# LPC55S66_cm33_core1 register map
Vendor: nxp.com; File version: 1.0
CPU: CM33 r2p0, little endian, no MPU, no FPU, VTOR, 3 interrupt priority bits
Registers are 32-bit, read-write, reset 0x0 unless marked. A register's access mark holds for its fields unless they carry their own. Offsets are from the block's base; [hi:lo] are bit positions; {n}, {i} and the like mark numbered series.

## RTC — Real-Time Clock (RTC)
Base 0x4002C000
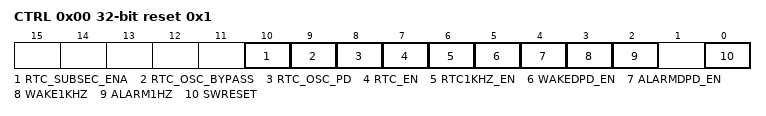
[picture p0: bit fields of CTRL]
0x00 CTRL reset 0x1 — RTC control register
  [10] RTC_SUBSEC_ENA — RTC Sub-second counter control.
    0=POWER_UP (The sub-second counter (if implemented) is disabled. This bit is cleared by a system-level POR or BOD reset as well as a by the RTC_ENA bit (bit 7 in this register). On modules not equipped with a sub-second counter, this bit will always read-back as a '0'.); 1=POWERED_DOWN (The 32 KHz sub-second counter is enabled (if implemented). Counting commences on the start of the first one-second interval after this bit is set. Note: This bit can only be set after the RTC_ENA bit (bit 7) is set by a previous write operation. Note: The RTC sub-second counter must be re-enabled whenever the chip exits deep power-down mode.)
  [9] RTC_OSC_BYPASS — RTC oscillator bypass control.
    0=USED (The RTC Oscillator operates normally as a crystal oscillator with the crystal connected between the RTC_XTALIN and RTC_XTALOUT pins.); 1=BYPASS (The RTC Oscillator is in bypass mode. In this mode a clock can be directly input into the RTC_XTALIN pin.)
  [8] RTC_OSC_PD — RTC oscillator power-down control.
    0=POWER_UP (See RTC_OSC_BYPASS); 1=POWERED_DOWN (RTC oscillator is powered-down.)
  [7] RTC_EN — RTC enable.
    0=DISABLE (Disable. The RTC 1 Hz and 1 kHz clocks are shut down and the RTC operation is disabled. This bit should be 0 when writing to load a value in the RTC counter register.); 1=ENABLE (Enable. The 1 Hz RTC clock is running and RTC operation is enabled. This bit must be set to initiate operation of the RTC. The first clock to the RTC counter occurs 1 s after this bit is set. To also enable the high-resolution, 1 kHz clock, set bit 6 in this register.)
  [6] RTC1KHZ_EN — RTC 1 kHz clock enable. This bit can be set to 0 to conserve power if the 1 kHz timer is not used. This bit has no effect when the RTC is disabled (bit 7 of this register is 0).
    0=DISABLE (Disable. A match on the 1 kHz RTC timer will not bring the part out of Deep power-down mode.); 1=ENABLE (Enable. The 1 kHz RTC timer is enabled.)
  [5] WAKEDPD_EN — RTC 1 kHz timer wake-up enable for Deep power-down.
    0=DISABLE (Disable. A match on the 1 kHz RTC timer will not bring the part out of Deep power-down mode.); 1=ENABLE (Enable. A match on the 1 kHz RTC timer bring the part out of Deep power-down mode.)
  [4] ALARMDPD_EN — RTC 1 Hz timer alarm enable for Deep power-down.
    0=DISABLE (Disable. A match on the 1 Hz RTC timer will not bring the part out of Deep power-down mode.); 1=ENABLE (Enable. A match on the 1 Hz RTC timer bring the part out of Deep power-down mode.)
  [3] WAKE1KHZ — RTC 1 kHz timer wake-up flag status.
    0=RUN (Run. The RTC 1 kHz timer is running. Writing a 0 has no effect.); 1=TIMEOUT (Time-out. The 1 kHz high-resolution/wake-up timer has timed out. This flag generates an RTC wake-up interrupt request RTC-WAKE which can also wake up the part from any low power mode. Writing a 1 clears this bit.)
  [2] ALARM1HZ — RTC 1 Hz timer alarm flag status.
    0=NO_MATCH (No match. No match has occurred on the 1 Hz RTC timer. Writing a 0 has no effect.); 1=MATCH (Match. A match condition has occurred on the 1 Hz RTC timer. This flag generates an RTC alarm interrupt request RTC_ALARM which can also wake up the part from any low power mode. Writing a 1 clears this bit.)
  [0] SWRESET — Software reset control
    0=NOT_IN_RESET (Not in reset. The RTC is not held in reset. This bit must be cleared prior to configuring or initiating any operation of the RTC.); 1=IN_RESET (In reset. The RTC is held in reset. All register bits within the RTC will be forced to their reset value except the OFD bit. This bit must be cleared before writing to any register in the RTC - including writes to set any of the other bits within this register. Do not attempt to write to any bits of this register at the same time that the reset bit is being cleared.)
0x04 MATCH reset 0xFFFFFFFF — RTC match register
  [31:0] MATVAL — Contains the match value against which the 1 Hz RTC timer will be compared to set the alarm flag RTC_ALARM and generate an alarm interrupt/wake-up if enabled.
0x08 COUNT — RTC counter register
  [31:0] VAL — A read reflects the current value of the main, 1 Hz RTC timer. A write loads a new initial value into the timer. The RTC counter will count up continuously at a 1 Hz rate once the RTC Software Reset is removed (by clearing bit 0 of the CTRL register). Only write to this register when the RTC_EN bit in the RTC CTRL Register is 0. The counter increments one second after the RTC_EN bit is set.
0x0C WAKE — High-resolution/wake-up timer control register
  [15:0] VAL — A read reflects the current value of the high-resolution/wake-up timer. A write pre-loads a start count value into the wake-up timer and initializes a count-down sequence. Do not write to this register while counting is in progress.
0x10 SUBSEC — Sub-second counter register
  [14:0] SUBSEC ro — A read reflects the current value of the 32KHz sub-second counter. This counter is cleared whenever the SUBSEC_ENA bit in the RTC_CONTROL register is low. Up-counting at a 32KHz rate commences at the start of the next one-second interval after the SUBSEC_ENA bit is set. This counter must be re-enabled after exiting deep power-down mode or after the main RTC module is disabled and re-enabled. On modules not equipped with a sub-second counter, this register will read-back as all zeroes.
{0x40+4i} GPREG[{i}] (i=0..7) — General Purpose register
  [31:0] GPDATA — Data retained during Deep power-down mode or loss of main power as long as VBAT is supplied.
